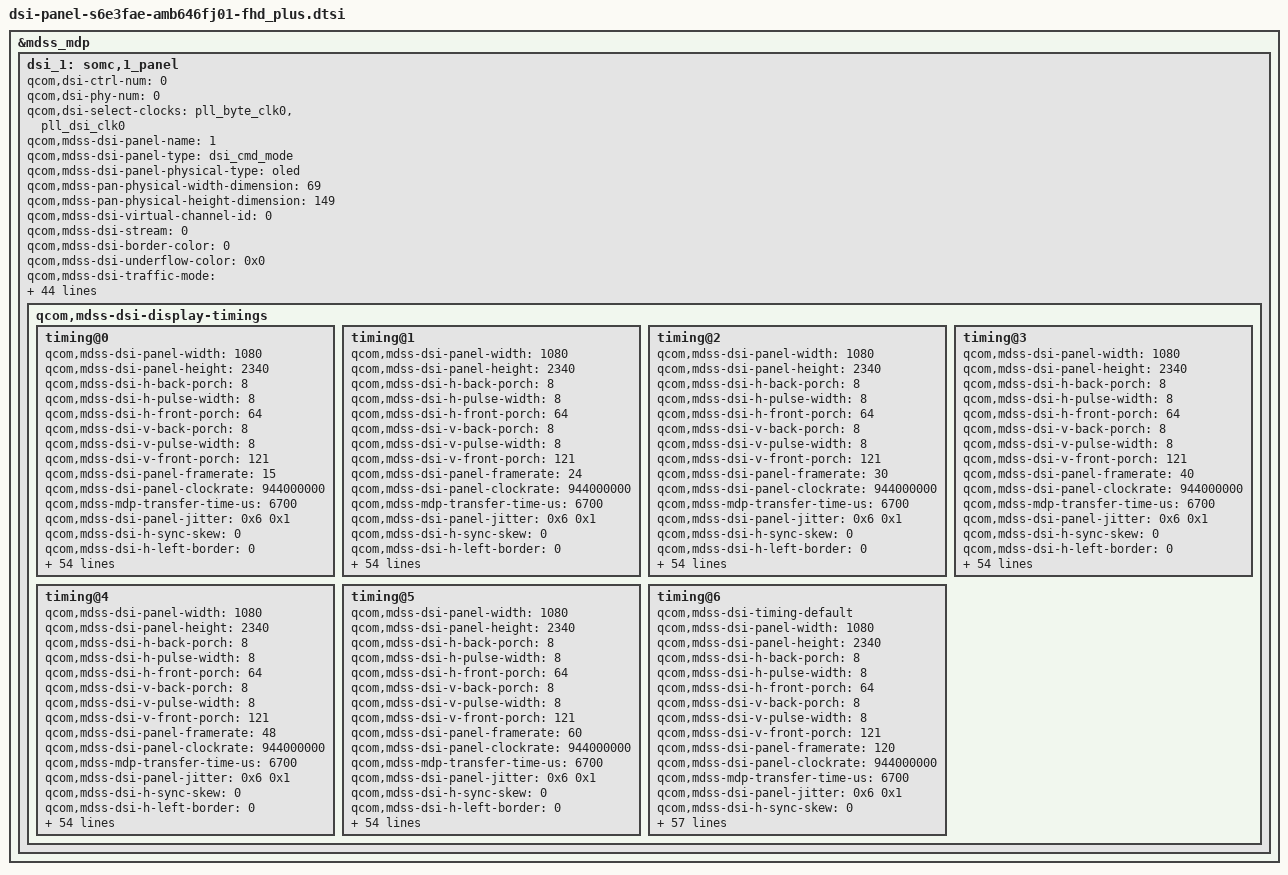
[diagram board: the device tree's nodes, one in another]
&mdss_mdp {
	/* Samsung FHD OLED ID1 */
	dsi_1: somc,1_panel {
		qcom,dsi-ctrl-num = <0>;
		qcom,dsi-phy-num = <0>;
		qcom,dsi-select-clocks = "pll_byte_clk0", "pll_dsi_clk0";

		qcom,mdss-dsi-panel-name = "1";
		qcom,mdss-dsi-panel-type = "dsi_cmd_mode";
		qcom,mdss-dsi-panel-physical-type = "oled";
		qcom,mdss-pan-physical-width-dimension = <69>;
		qcom,mdss-pan-physical-height-dimension = <149>;
		qcom,mdss-dsi-virtual-channel-id = <0>;
		qcom,mdss-dsi-stream = <0>;
		qcom,mdss-dsi-border-color = <0>;
		qcom,mdss-dsi-underflow-color = <0x0>;
		qcom,mdss-dsi-traffic-mode = "non_burst_sync_event";
		qcom,mdss-dsi-bllp-eof-power-mode;
		qcom,mdss-dsi-bllp-power-mode;
		qcom,mdss-dsi-dma-trigger = "trigger_sw";
		qcom,mdss-dsi-mdp-trigger = "none";
		qcom,mdss-dsi-te-using-te-pin;
		qcom,mdss-dsi-te-pin-select = <1>;
		qcom,mdss-dsi-te-dcs-command = <1>;
		qcom,mdss-dsi-te-check-enable;
		qcom,mdss-dsi-tx-eot-append;
		qcom,mdss-dsi-wr-mem-start = <0x2c>;
		qcom,mdss-dsi-wr-mem-continue = <0x3c>;
		qcom,mdss-dsi-bpp = <24>;
		qcom,mdss-dsi-lane-0-state;
		qcom,mdss-dsi-lane-1-state;
		qcom,mdss-dsi-lane-2-state;
		qcom,mdss-dsi-lane-3-state;
		qcom,mdss-dsi-lp11-init;

		somc,area_count_table_size = <45>;
		somc,area_count_table = <0 50 101 152 203
				254 306 357 408 459
				510 613 715 818 920
				1022 1125 1227 1330 1432
				1534 1637 1739 1842 1944
				2047 2162 2279 2396 2513
				2630 2747 2865 2982 3099
				3216 3333 3450 3567 3685
				3802 3919 4036 4094 4095>;

		somc,brightness-adjust-type = <2>;

		somc,pw-wait-before-on-lp11 = <10>;
		somc,mdss-dsi-touch-reset-sequence = <1 0>;
		somc,pw-wait-before-panel-reset = <1>;
		qcom,mdss-dsi-reset-sequence = <1 5>;

		somc,pw-wait-after-off-lp11 = <1>;
		somc,pw-off-rst-b-seq = <0 0>;
		somc,pw-wait-after-off-touch-vddh = <10>;
		somc,pw-wait-down_period = <100>;

		qcom,mdss-dsi-panel-peak-brightness = <15000000>;
		qcom,mdss-dsi-panel-blackness-level = <100>;
		qcom,mdss-dsi-panel-hdr-enabled;
		qcom,mdss-dsi-panel-hdr-color-primaries = <15335 15900 33905 15980 12475 35285 7205 2195>;

		qcom,esd-check-enabled;
		qcom,mdss-dsi-panel-status-command = [06 01 00 01 05 00 01 0A];
		qcom,mdss-dsi-panel-status-command-state = "dsi_lp_mode";
		qcom,mdss-dsi-panel-status-check-mode = "reg_read";
		qcom,mdss-dsi-panel-status-read-length = <1>;
		qcom,mdss-dsi-panel-status-value = <0x9f>;

		qcom,mdss-dsi-display-timings {
			/* FHD 15FPS */
			timing@0 {
				qcom,mdss-dsi-panel-width = <1080>;
				qcom,mdss-dsi-panel-height = <2340>;
				qcom,mdss-dsi-h-back-porch = <8>;
				qcom,mdss-dsi-h-pulse-width = <8>;
				qcom,mdss-dsi-h-front-porch = <64>;
				qcom,mdss-dsi-v-back-porch = <8>;
				qcom,mdss-dsi-v-pulse-width = <8>;
				qcom,mdss-dsi-v-front-porch = <121>;
				qcom,mdss-dsi-panel-framerate = <15>;
				qcom,mdss-dsi-panel-clockrate = <944000000>;
				qcom,mdss-mdp-transfer-time-us = <6700>;
				qcom,mdss-dsi-panel-jitter = <0x6 0x1>;
				qcom,mdss-dsi-h-sync-skew = <0>;
				qcom,mdss-dsi-h-left-border = <0>;
				qcom,mdss-dsi-h-right-border = <0>;
				qcom,mdss-dsi-v-top-border = <0>;
				qcom,mdss-dsi-v-bottom-border = <0>;
				qcom,mdss-dsi-h-sync-pulse = <1>;
				qcom,mdss-dsi-on-command-state = "dsi_lp_mode";
				qcom,mdss-dsi-post-on-command-state = "dsi_lp_mode";
				qcom,mdss-dsi-off-command-state = "dsi_hs_mode";

				qcom,compression-mode = "dsc";
				qcom,mdss-dsc-slice-height = <60>;
				qcom,mdss-dsc-slice-width = <540>;
				qcom,mdss-dsc-slice-per-pkt = <2>;
				qcom,mdss-dsc-bit-per-component = <8>;
				qcom,mdss-dsc-bit-per-pixel = <8>;
				qcom,mdss-dsc-encoders = <2>;
				qcom,mdss-dsc-block-prediction-enable;

				qcom,mdss-dsi-on-command = [
					05 01 00 00 78 00 01 11
					/* 245 */
					39 01 00 00 00 00 03 F0 5A 5A
					39 01 00 00 00 00 04 B0 00 01 F2
					39 01 00 00 00 00 02 F2 00
					39 01 00 00 00 00 02 F7 2F
					39 01 00 00 00 00 03 F0 A5 A5
					/* 245 */
					39 01 00 00 00 00 02 35 00
					39 01 00 00 00 00 05 2A 00 00 04 37
					39 01 00 00 00 00 05 2B 00 00 09 23
					39 01 00 00 00 00 03 F0 5A 5A
					39 01 00 00 00 00 04 B0 00 10 BD
					39 01 00 00 00 00 02 BD 00
					39 01 00 00 00 00 02 83 06
					39 01 00 00 00 00 04 B0 00 01 BD
					39 01 00 00 00 00 02 BD 81
					39 01 00 00 00 00 02 BD 01
					39 01 00 00 00 00 02 F7 2F
					39 01 00 00 00 00 03 F0 A5 A5
					39 01 00 00 00 00 03 F0 5A 5A
					39 01 00 00 00 00 03 FC 5A 5A
					39 01 00 00 00 00 04 B0 00 3C C5
					39 01 00 00 00 00 03 C5 43 A9
					39 01 00 00 00 00 04 B0 00 36 C5
					39 01 00 00 00 00 05 C5 11 10 50 05
					39 01 00 00 00 00 03 FC A5 A5
					39 01 00 00 00 00 03 F0 A5 A5
					39 01 00 00 00 00 02 55 00
					39 01 00 00 00 00 03 F0 5A 5A
					39 01 00 00 00 00 04 B0 00 08 68
					39 01 00 00 00 00 02 68 1E
					39 01 00 00 00 00 04 B0 00 03 68
					39 01 00 00 00 00 02 68 25
					39 01 00 00 00 00 03 F0 A5 A5
					39 01 00 00 00 00 03 F0 5A 5A
					39 01 00 00 00 00 02 E5 15
					39 01 00 00 00 00 04 B0 00 5F F4
					39 01 00 00 00 00 02 F4 F4
					39 01 00 00 00 00 04 B0 00 67 F4
					39 01 00 00 00 00 02 F4 AA
					39 01 00 00 00 00 04 B0 00 17 ED
					39 01 00 00 00 00 02 ED 1C
					39 01 00 00 00 00 03 ED 0B 4C
					39 01 00 00 00 00 04 B0 00 03 ED
					39 01 00 00 00 00 02 ED 0D
					39 01 00 00 00 00 03 F0 A5 A5
					39 01 00 00 00 00 02 53 28
					39 01 00 00 00 00 03 F0 5A 5A
					39 01 00 00 00 00 04 B0 00 17 69
					39 01 00 00 00 00 02 69 08
					39 01 00 00 00 00 02 F7 2F
					39 01 00 00 00 00 03 F0 A5 A5
					39 01 00 00 00 00 02 9D 01
					05 01 00 00 14 00 01 28
					39 01 00 00 00 00 03 F0 5A 5A
					39 01 00 00 00 00 02 B9 50
					39 01 00 00 00 00 02 F7 2F
					39 01 00 00 00 00 03 F0 A5 A5
					39 01 00 00 00 00 03 F0 5A 5A
					39 01 00 00 00 00 04 B0 00 10 BD
					39 01 00 00 00 00 02 BD 00
					39 01 00 00 00 00 02 83 00
					39 01 00 00 00 00 04 B0 00 01 BD
					39 01 00 00 00 00 02 BD 81
					39 01 00 00 00 00 02 BD 01
					39 01 00 00 00 00 02 F7 2F
					39 01 00 00 00 00 03 F0 A5 A5
					05 01 00 00 0A 00 01 28
					39 01 00 00 00 00 02 53 24
					39 01 00 00 00 00 03 51 02 80
					39 01 00 00 00 00 03 F0 5A 5A
					39 01 00 00 00 00 02 BD 01
					39 01 00 00 00 00 04 B0 00 02 BD
					39 01 00 00 00 00 02 BD 00
					39 01 00 00 00 00 04 B0 00 E8 BD
					39 01 00 00 00 00 02 BD 40
					39 01 00 00 00 00 04 B0 00 01 83
					39 01 00 00 00 00 02 83 01
					39 01 00 00 00 00 02 F7 2F
					39 01 00 00 00 00 03 F0 A5 A5
					05 01 00 00 00 00 01 29
					05 01 00 00 0A 00 01 28
					39 01 00 00 00 00 02 53 20
					39 01 00 00 00 00 03 51 00 04
					39 01 00 00 00 00 03 F0 5A 5A
					39 01 00 00 00 00 04 B0 00 10 BD
					39 01 00 00 00 00 02 BD 00
					39 01 00 00 00 00 02 83 06
					39 01 00 00 00 00 04 B0 00 01 BD
					39 01 00 00 00 00 02 BD 81
					39 01 00 00 00 00 02 BD 01
					39 01 00 00 00 00 02 F7 2F
					39 01 00 00 00 00 03 F0 A5 A5
					05 01 00 00 00 00 01 29
					];
				qcom,mdss-dsi-post-panel-on-command = [
					05 01 00 00 00 00 01 29];
				qcom,mdss-dsi-off-command = [
					05 01 00 00 14 00 01 28
					05 01 00 00 78 00 01 10];
				qcom,mdss-dsi-timing-switch-command = [
					39 01 00 00 00 00 03 F0 5A 5A
					39 01 00 00 00 00 04 B0 00 17 69
					39 01 00 00 00 00 02 69 08
					39 01 00 00 00 00 03 F0 A5 A5
					39 01 00 00 00 00 03 F0 5A 5A
					39 01 00 00 00 00 02 83 00
					39 01 00 00 00 00 02 F7 2F
					39 01 00 00 3C 00 03 F0 A5 A5
					39 01 00 00 00 00 03 F0 5A 5A
					39 01 00 00 00 00 02 B9 51
					39 01 00 00 00 00 04 B0 00 08 B9
					39 01 00 00 00 00 0D B9 00 09 44 00 00 20 00 09 44 00 00 20
					39 01 00 00 00 00 04 B0 00 02 B9
					39 01 00 00 00 00 02 B9 07
					39 01 00 00 00 00 02 B9 51
					39 01 00 00 00 00 02 F7 2F
					39 01 00 00 00 00 03 F0 A5 A5
					39 01 00 00 00 00 03 F0 5A 5A
					39 01 00 00 00 00 04 B0 00 93 BD
					39 01 00 00 00 00 02 BD 0E
					39 01 00 00 00 00 04 B0 00 83 BD
					39 01 00 00 00 00 02 BD 01
					39 01 00 00 00 00 04 B0 00 80 BD
					39 01 00 00 00 00 02 BD 16
					39 01 00 00 00 00 04 B0 00 9E BD
					39 01 00 00 00 00 11 BD 00 0E 00 0E 00 0E 00 0E 00 0E 00 0E 00 0E 00 0E
					39 01 00 00 00 00 04 B0 00 AE BD
					39 01 00 00 00 00 09 BD 00 00 00 00 00 00 00 00
					39 01 00 00 00 00 04 B0 00 1C BD
					39 01 00 00 00 00 02 BD EE
					39 01 00 00 00 00 04 B0 00 01 BD
					39 01 00 00 00 00 02 BD 01
					39 01 00 00 00 00 02 BD 83
					39 01 00 00 00 00 02 F7 2F
					39 01 00 00 00 00 03 F0 A5 A5
					05 01 00 00 00 00 01 29
					];
				qcom,mdss-dsi-timing-switch-command-state = "dsi_hs_mode";
				somc,mdss-dsi-flm2-on-command = [
					39 01 00 00 00 00 03 F0 5A 5A
					39 01 00 00 00 00 04 B0 00 03 68
					39 01 00 00 00 00 02 68 25
					39 01 00 00 00 00 03 F0 A5 A5
					];
				somc,mdss-dsi-flm2-off-command = [
					39 01 00 00 00 00 03 F0 5A 5A
					39 01 00 00 00 00 04 B0 00 03 68
					39 01 00 00 00 00 02 68 05
					39 01 00 00 00 00 03 F0 A5 A5
					];
				somc,mdss-dsi-flm2-on-command-state = "dsi_lp_mode";
				somc,mdss-dsi-flm2-off-command-state = "dsi_lp_mode";
				qcom,mdss-dsi-lp1-command = [
					05 01 00 00 14 00 01 28
					39 01 00 00 00 00 03 F0 5A 5A
					39 01 00 00 00 00 02 B9 50
					39 01 00 00 00 00 02 F7 2F
					39 01 00 00 00 00 03 F0 A5 A5
					39 01 00 00 00 00 03 F0 5A 5A
					39 01 00 00 00 00 04 B0 00 10 BD
					39 01 00 00 00 00 02 BD 00
					39 01 00 00 00 00 02 83 00
					39 01 00 00 00 00 04 B0 00 01 BD
					39 01 00 00 00 00 02 BD 81
					39 01 00 00 00 00 02 BD 01
					39 01 00 00 00 00 02 F7 2F
					39 01 00 00 00 00 03 F0 A5 A5
					05 01 00 00 0A 00 01 28
					39 01 00 00 00 00 02 53 24
					39 01 00 00 00 00 03 51 02 80
					39 01 00 00 00 00 03 F0 5A 5A
					39 01 00 00 00 00 02 BD 01
					39 01 00 00 00 00 04 B0 00 02 BD
					39 01 00 00 00 00 02 BD 00
					39 01 00 00 00 00 04 B0 00 E8 BD
					39 01 00 00 00 00 02 BD 40
					39 01 00 00 00 00 04 B0 00 01 83
					39 01 00 00 00 00 02 83 01
					39 01 00 00 00 00 02 F7 2F
					39 01 00 00 00 00 03 F0 A5 A5
					05 01 00 00 00 00 01 29
					];
				qcom,mdss-dsi-nolp-command = [
					05 01 00 00 0A 00 01 28
					39 01 00 00 00 00 02 53 20
					39 01 00 00 00 00 03 51 00 04
					05 01 00 00 00 00 01 29
					/*dimming control*/
					39 01 00 00 00 00 02 53 28
					];
				qcom,mdss-dsi-lp1-command-state = "dsi_lp_mode";
				qcom,mdss-dsi-nolp-command-state = "dsi_lp_mode";
				somc,mdss-dsi-hmd-on-command = [
					];
				somc,mdss-dsi-hmd-off-command = [
					];
				somc,mdss-dsi-hmd-on-command-state = "dsi_hs_mode";
				somc,mdss-dsi-hmd-off-command-state = "dsi_hs_mode";

				somc,mdss-dsi-aod-low-command = [
					39 01 00 00 00 00 03 51 02 80
					];
				somc,mdss-dsi-aod-high-command = [
					39 01 00 00 00 00 03 51 07 FF
					];
				somc,mdss-dsi-aod-low-command-state = "dsi_lp_mode";
				somc,mdss-dsi-aod-high-command-state = "dsi_lp_mode";
			};

			/* FHD 24FPS */
			timing@1 {
				qcom,mdss-dsi-panel-width = <1080>;
				qcom,mdss-dsi-panel-height = <2340>;
				qcom,mdss-dsi-h-back-porch = <8>;
				qcom,mdss-dsi-h-pulse-width = <8>;
				qcom,mdss-dsi-h-front-porch = <64>;
				qcom,mdss-dsi-v-back-porch = <8>;
				qcom,mdss-dsi-v-pulse-width = <8>;
				qcom,mdss-dsi-v-front-porch = <121>;
				qcom,mdss-dsi-panel-framerate = <24>;
				qcom,mdss-dsi-panel-clockrate = <944000000>;
				qcom,mdss-mdp-transfer-time-us = <6700>;
				qcom,mdss-dsi-panel-jitter = <0x6 0x1>;
				qcom,mdss-dsi-h-sync-skew = <0>;
				qcom,mdss-dsi-h-left-border = <0>;
				qcom,mdss-dsi-h-right-border = <0>;
				qcom,mdss-dsi-v-top-border = <0>;
				qcom,mdss-dsi-v-bottom-border = <0>;
				qcom,mdss-dsi-h-sync-pulse = <1>;
				qcom,mdss-dsi-on-command-state = "dsi_lp_mode";
				qcom,mdss-dsi-post-on-command-state = "dsi_lp_mode";
				qcom,mdss-dsi-off-command-state = "dsi_hs_mode";

				qcom,compression-mode = "dsc";
				qcom,mdss-dsc-slice-height = <60>;
				qcom,mdss-dsc-slice-width = <540>;
				qcom,mdss-dsc-slice-per-pkt = <2>;
				qcom,mdss-dsc-bit-per-component = <8>;
				qcom,mdss-dsc-bit-per-pixel = <8>;
				qcom,mdss-dsc-encoders = <2>;
				qcom,mdss-dsc-block-prediction-enable;

				qcom,mdss-dsi-on-command = [
					05 01 00 00 78 00 01 11
					/* 245 */
					39 01 00 00 00 00 03 F0 5A 5A
					39 01 00 00 00 00 04 B0 00 01 F2
					39 01 00 00 00 00 02 F2 00
					39 01 00 00 00 00 02 F7 2F
					39 01 00 00 00 00 03 F0 A5 A5
					/* 245 */
					39 01 00 00 00 00 02 35 00
					39 01 00 00 00 00 05 2A 00 00 04 37
					39 01 00 00 00 00 05 2B 00 00 09 23
					39 01 00 00 00 00 03 F0 5A 5A
					39 01 00 00 00 00 04 B0 00 10 BD
					39 01 00 00 00 00 02 BD 00
					39 01 00 00 00 00 02 83 05
					39 01 00 00 00 00 04 B0 00 01 BD
					39 01 00 00 00 00 02 BD 81
					39 01 00 00 00 00 02 BD 01
					39 01 00 00 00 00 02 F7 2F
					39 01 00 00 00 00 03 F0 A5 A5
					39 01 00 00 00 00 03 F0 5A 5A
					39 01 00 00 00 00 03 FC 5A 5A
					39 01 00 00 00 00 04 B0 00 3C C5
					39 01 00 00 00 00 03 C5 43 A9
					39 01 00 00 00 00 04 B0 00 36 C5
					39 01 00 00 00 00 05 C5 11 10 50 05
					39 01 00 00 00 00 03 FC A5 A5
					39 01 00 00 00 00 03 F0 A5 A5
					39 01 00 00 00 00 02 55 00
					39 01 00 00 00 00 03 F0 5A 5A
					39 01 00 00 00 00 04 B0 00 08 68
					39 01 00 00 00 00 02 68 1E
					39 01 00 00 00 00 04 B0 00 03 68
					39 01 00 00 00 00 02 68 25
					39 01 00 00 00 00 03 F0 A5 A5
					39 01 00 00 00 00 03 F0 5A 5A
					39 01 00 00 00 00 02 E5 15
					39 01 00 00 00 00 04 B0 00 5F F4
					39 01 00 00 00 00 02 F4 F4
					39 01 00 00 00 00 04 B0 00 67 F4
					39 01 00 00 00 00 02 F4 AA
					39 01 00 00 00 00 04 B0 00 17 ED
					39 01 00 00 00 00 02 ED 1C
					39 01 00 00 00 00 03 ED 0B 4C
					39 01 00 00 00 00 04 B0 00 03 ED
					39 01 00 00 00 00 02 ED 0D
					39 01 00 00 00 00 03 F0 A5 A5
					39 01 00 00 00 00 02 53 28
					39 01 00 00 00 00 03 F0 5A 5A
					39 01 00 00 00 00 04 B0 00 17 69
					39 01 00 00 00 00 02 69 08
					39 01 00 00 00 00 02 F7 2F
					39 01 00 00 00 00 03 F0 A5 A5
					39 01 00 00 00 00 02 9D 01
					05 01 00 00 14 00 01 28
					39 01 00 00 00 00 03 F0 5A 5A
					39 01 00 00 00 00 02 B9 50
					39 01 00 00 00 00 02 F7 2F
					39 01 00 00 00 00 03 F0 A5 A5
					39 01 00 00 00 00 03 F0 5A 5A
					39 01 00 00 00 00 04 B0 00 10 BD
					39 01 00 00 00 00 02 BD 00
					39 01 00 00 00 00 02 83 00
					39 01 00 00 00 00 04 B0 00 01 BD
					39 01 00 00 00 00 02 BD 81
					39 01 00 00 00 00 02 BD 01
					39 01 00 00 00 00 02 F7 2F
					39 01 00 00 00 00 03 F0 A5 A5
					05 01 00 00 0A 00 01 28
					39 01 00 00 00 00 02 53 24
					39 01 00 00 00 00 03 51 02 80
					39 01 00 00 00 00 03 F0 5A 5A
					39 01 00 00 00 00 02 BD 01
					39 01 00 00 00 00 04 B0 00 02 BD
					39 01 00 00 00 00 02 BD 00
					39 01 00 00 00 00 04 B0 00 E8 BD
					39 01 00 00 00 00 02 BD 40
					39 01 00 00 00 00 04 B0 00 01 83
					39 01 00 00 00 00 02 83 01
					39 01 00 00 00 00 02 F7 2F
					39 01 00 00 00 00 03 F0 A5 A5
					05 01 00 00 00 00 01 29
					05 01 00 00 0A 00 01 28
					39 01 00 00 00 00 02 53 20
					39 01 00 00 00 00 03 51 00 04
					39 01 00 00 00 00 03 F0 5A 5A
					39 01 00 00 00 00 04 B0 00 10 BD
					39 01 00 00 00 00 02 BD 00
					39 01 00 00 00 00 02 83 05
					39 01 00 00 00 00 04 B0 00 01 BD
					39 01 00 00 00 00 02 BD 81
					39 01 00 00 00 00 02 BD 01
					39 01 00 00 00 00 02 F7 2F
					39 01 00 00 00 00 03 F0 A5 A5
					05 01 00 00 00 00 01 29
					];
				qcom,mdss-dsi-post-panel-on-command = [
					05 01 00 00 00 00 01 29];
				qcom,mdss-dsi-off-command = [
					05 01 00 00 14 00 01 28
					05 01 00 00 78 00 01 10];
				qcom,mdss-dsi-timing-switch-command = [
					39 01 00 00 00 00 03 F0 5A 5A
					39 01 00 00 00 00 02 B9 50
					39 01 00 00 00 00 02 F7 2F
					39 01 00 00 00 00 03 F0 A5 A5
					39 01 00 00 00 00 03 F0 5A 5A
					39 01 00 00 00 00 04 B0 00 10 BD
					39 01 00 00 00 00 02 BD 00
					39 01 00 00 00 00 02 83 05
					39 01 00 00 00 00 04 B0 00 01 BD
					39 01 00 00 00 00 02 BD 81
					39 01 00 00 00 00 02 BD 01
					39 01 00 00 00 00 02 F7 2F
					39 01 00 00 00 00 03 F0 A5 A5
					05 01 00 00 07 00 01 29
					];
				qcom,mdss-dsi-timing-switch-command-state = "dsi_hs_mode";
				somc,mdss-dsi-flm2-on-command = [
					39 01 00 00 00 00 03 F0 5A 5A
					39 01 00 00 00 00 04 B0 00 03 68
					39 01 00 00 00 00 02 68 25
					39 01 00 00 00 00 03 F0 A5 A5
					];
				somc,mdss-dsi-flm2-off-command = [
					39 01 00 00 00 00 03 F0 5A 5A
					39 01 00 00 00 00 04 B0 00 03 68
					39 01 00 00 00 00 02 68 05
					39 01 00 00 00 00 03 F0 A5 A5
					];
				somc,mdss-dsi-flm2-on-command-state = "dsi_lp_mode";
				somc,mdss-dsi-flm2-off-command-state = "dsi_lp_mode";
				qcom,mdss-dsi-lp1-command = [
					05 01 00 00 14 00 01 28
					39 01 00 00 00 00 03 F0 5A 5A
					39 01 00 00 00 00 02 B9 50
					39 01 00 00 00 00 02 F7 2F
					39 01 00 00 00 00 03 F0 A5 A5
					39 01 00 00 00 00 03 F0 5A 5A
					39 01 00 00 00 00 04 B0 00 10 BD
					39 01 00 00 00 00 02 BD 00
					39 01 00 00 00 00 02 83 00
					39 01 00 00 00 00 04 B0 00 01 BD
					39 01 00 00 00 00 02 BD 81
					39 01 00 00 00 00 02 BD 01
					39 01 00 00 00 00 02 F7 2F
					39 01 00 00 00 00 03 F0 A5 A5
					05 01 00 00 0A 00 01 28
					39 01 00 00 00 00 02 53 24
					39 01 00 00 00 00 03 51 02 80
					39 01 00 00 00 00 03 F0 5A 5A
					39 01 00 00 00 00 02 BD 01
					39 01 00 00 00 00 04 B0 00 02 BD
					39 01 00 00 00 00 02 BD 00
					39 01 00 00 00 00 04 B0 00 E8 BD
					39 01 00 00 00 00 02 BD 40
					39 01 00 00 00 00 04 B0 00 01 83
					39 01 00 00 00 00 02 83 01
					39 01 00 00 00 00 02 F7 2F
					39 01 00 00 00 00 03 F0 A5 A5
					05 01 00 00 00 00 01 29
					];
				qcom,mdss-dsi-nolp-command = [
					05 01 00 00 0A 00 01 28
					39 01 00 00 00 00 02 53 20
					39 01 00 00 00 00 03 51 00 04
					05 01 00 00 00 00 01 29
					/*dimming control*/
					39 01 00 00 00 00 02 53 28
					];
				qcom,mdss-dsi-lp1-command-state = "dsi_lp_mode";
				qcom,mdss-dsi-nolp-command-state = "dsi_lp_mode";
				somc,mdss-dsi-hmd-on-command = [
					];
				somc,mdss-dsi-hmd-off-command = [
					];
				somc,mdss-dsi-hmd-on-command-state = "dsi_hs_mode";
				somc,mdss-dsi-hmd-off-command-state = "dsi_hs_mode";

				somc,mdss-dsi-aod-low-command = [
					39 01 00 00 00 00 03 51 02 80
					];
				somc,mdss-dsi-aod-high-command = [
					39 01 00 00 00 00 03 51 07 FF
					];
				somc,mdss-dsi-aod-low-command-state = "dsi_lp_mode";
				somc,mdss-dsi-aod-high-command-state = "dsi_lp_mode";
			};

			/* FHD 30FPS */
			timing@2 {
				qcom,mdss-dsi-panel-width = <1080>;
				qcom,mdss-dsi-panel-height = <2340>;
				qcom,mdss-dsi-h-back-porch = <8>;
				qcom,mdss-dsi-h-pulse-width = <8>;
				qcom,mdss-dsi-h-front-porch = <64>;
				qcom,mdss-dsi-v-back-porch = <8>;
				qcom,mdss-dsi-v-pulse-width = <8>;
				qcom,mdss-dsi-v-front-porch = <121>;
				qcom,mdss-dsi-panel-framerate = <30>;
				qcom,mdss-dsi-panel-clockrate = <944000000>;
				qcom,mdss-mdp-transfer-time-us = <6700>;
				qcom,mdss-dsi-panel-jitter = <0x6 0x1>;
				qcom,mdss-dsi-h-sync-skew = <0>;
				qcom,mdss-dsi-h-left-border = <0>;
				qcom,mdss-dsi-h-right-border = <0>;
				qcom,mdss-dsi-v-top-border = <0>;
				qcom,mdss-dsi-v-bottom-border = <0>;
				qcom,mdss-dsi-h-sync-pulse = <1>;
				qcom,mdss-dsi-on-command-state = "dsi_lp_mode";
				qcom,mdss-dsi-post-on-command-state = "dsi_lp_mode";
				qcom,mdss-dsi-off-command-state = "dsi_hs_mode";

				qcom,compression-mode = "dsc";
				qcom,mdss-dsc-slice-height = <60>;
				qcom,mdss-dsc-slice-width = <540>;
				qcom,mdss-dsc-slice-per-pkt = <2>;
				qcom,mdss-dsc-bit-per-component = <8>;
				qcom,mdss-dsc-bit-per-pixel = <8>;
				qcom,mdss-dsc-encoders = <2>;
				qcom,mdss-dsc-block-prediction-enable;

				qcom,mdss-dsi-on-command = [
					05 01 00 00 78 00 01 11
					/* 245 */
					39 01 00 00 00 00 03 F0 5A 5A
					39 01 00 00 00 00 04 B0 00 01 F2
					39 01 00 00 00 00 02 F2 00
					39 01 00 00 00 00 02 F7 2F
					39 01 00 00 00 00 03 F0 A5 A5
					/* 245 */
					39 01 00 00 00 00 02 35 00
					39 01 00 00 00 00 05 2A 00 00 04 37
					39 01 00 00 00 00 05 2B 00 00 09 23
					39 01 00 00 00 00 03 F0 5A 5A
					39 01 00 00 00 00 04 B0 00 10 BD
					39 01 00 00 00 00 02 BD 00
					39 01 00 00 00 00 02 83 04
					39 01 00 00 00 00 04 B0 00 01 BD
					39 01 00 00 00 00 02 BD 81
					39 01 00 00 00 00 02 BD 01
					39 01 00 00 00 00 02 F7 2F
					39 01 00 00 00 00 03 F0 A5 A5
					39 01 00 00 00 00 03 F0 5A 5A
					39 01 00 00 00 00 03 FC 5A 5A
					39 01 00 00 00 00 04 B0 00 3C C5
					39 01 00 00 00 00 03 C5 43 A9
					39 01 00 00 00 00 04 B0 00 36 C5
					39 01 00 00 00 00 05 C5 11 10 50 05
					39 01 00 00 00 00 03 FC A5 A5
					39 01 00 00 00 00 03 F0 A5 A5
					39 01 00 00 00 00 02 55 00
					39 01 00 00 00 00 03 F0 5A 5A
					39 01 00 00 00 00 04 B0 00 08 68
					39 01 00 00 00 00 02 68 1E
					39 01 00 00 00 00 04 B0 00 03 68
					39 01 00 00 00 00 02 68 25
					39 01 00 00 00 00 03 F0 A5 A5
					39 01 00 00 00 00 03 F0 5A 5A
					39 01 00 00 00 00 02 E5 15
					39 01 00 00 00 00 04 B0 00 5F F4
					39 01 00 00 00 00 02 F4 F4
					39 01 00 00 00 00 04 B0 00 67 F4
					39 01 00 00 00 00 02 F4 AA
					39 01 00 00 00 00 04 B0 00 17 ED
					39 01 00 00 00 00 02 ED 1C
					39 01 00 00 00 00 03 ED 0B 4C
					39 01 00 00 00 00 04 B0 00 03 ED
					39 01 00 00 00 00 02 ED 0D
					39 01 00 00 00 00 03 F0 A5 A5
					39 01 00 00 00 00 02 53 28
					39 01 00 00 00 00 03 F0 5A 5A
					39 01 00 00 00 00 04 B0 00 17 69
					39 01 00 00 00 00 02 69 08
					39 01 00 00 00 00 02 F7 2F
					39 01 00 00 00 00 03 F0 A5 A5
					39 01 00 00 00 00 02 9D 01
					05 01 00 00 14 00 01 28
					39 01 00 00 00 00 03 F0 5A 5A
					39 01 00 00 00 00 02 B9 50
					39 01 00 00 00 00 02 F7 2F
					39 01 00 00 00 00 03 F0 A5 A5
					39 01 00 00 00 00 03 F0 5A 5A
					39 01 00 00 00 00 04 B0 00 10 BD
					39 01 00 00 00 00 02 BD 00
					39 01 00 00 00 00 02 83 00
					39 01 00 00 00 00 04 B0 00 01 BD
					39 01 00 00 00 00 02 BD 81
					39 01 00 00 00 00 02 BD 01
					39 01 00 00 00 00 02 F7 2F
					39 01 00 00 00 00 03 F0 A5 A5
					05 01 00 00 0A 00 01 28
					39 01 00 00 00 00 02 53 24
					39 01 00 00 00 00 03 51 02 80
					39 01 00 00 00 00 03 F0 5A 5A
					39 01 00 00 00 00 02 BD 01
					39 01 00 00 00 00 04 B0 00 02 BD
					39 01 00 00 00 00 02 BD 00
					39 01 00 00 00 00 04 B0 00 E8 BD
					39 01 00 00 00 00 02 BD 40
					39 01 00 00 00 00 04 B0 00 01 83
					39 01 00 00 00 00 02 83 01
					39 01 00 00 00 00 02 F7 2F
					39 01 00 00 00 00 03 F0 A5 A5
					05 01 00 00 00 00 01 29
					05 01 00 00 0A 00 01 28
					39 01 00 00 00 00 02 53 20
					39 01 00 00 00 00 03 51 00 04
					39 01 00 00 00 00 03 F0 5A 5A
					39 01 00 00 00 00 04 B0 00 10 BD
					39 01 00 00 00 00 02 BD 00
					39 01 00 00 00 00 02 83 04
					39 01 00 00 00 00 04 B0 00 01 BD
					39 01 00 00 00 00 02 BD 81
					39 01 00 00 00 00 02 BD 01
					39 01 00 00 00 00 02 F7 2F
					39 01 00 00 00 00 03 F0 A5 A5
					05 01 00 00 00 00 01 29
					];
				qcom,mdss-dsi-post-panel-on-command = [
					05 01 00 00 00 00 01 29];
				qcom,mdss-dsi-off-command = [
					05 01 00 00 14 00 01 28
					05 01 00 00 78 00 01 10];
				qcom,mdss-dsi-timing-switch-command = [
					39 01 00 00 00 00 03 F0 5A 5A
					39 01 00 00 00 00 04 B0 00 17 69
					39 01 00 00 00 00 02 69 08
					39 01 00 00 00 00 03 F0 A5 A5
					39 01 00 00 00 00 03 F0 5A 5A
					39 01 00 00 00 00 02 83 00
					39 01 00 00 00 00 02 F7 2F
					39 01 00 00 3C 00 03 F0 A5 A5
					39 01 00 00 00 00 03 F0 5A 5A
					39 01 00 00 00 00 04 B0 00 08 B9
					39 01 00 00 00 00 0D B9 00 09 44 00 00 20 00 09 44 00 00 20
					39 01 00 00 00 00 04 B0 00 02 B9
					39 01 00 00 00 00 02 B9 03
					39 01 00 00 00 00 02 B9 51
					39 01 00 00 00 00 02 F7 2F
					39 01 00 00 00 00 03 F0 A5 A5
					39 01 00 00 00 00 03 F0 5A 5A
					39 01 00 00 00 00 04 B0 00 93 BD
					39 01 00 00 00 00 02 BD 06
					39 01 00 00 00 00 04 B0 00 83 BD
					39 01 00 00 00 00 02 BD 01
					39 01 00 00 00 00 04 B0 00 80 BD
					39 01 00 00 00 00 02 BD 16
					39 01 00 00 00 00 04 B0 00 9E BD
					39 01 00 00 00 00 11 BD 00 06 00 06 00 06 00 06 00 06 00 06 00 06 00 06
					39 01 00 00 00 00 04 B0 00 AE BD
					39 01 00 00 00 00 09 BD 00 00 00 00 00 00 00 00
					39 01 00 00 00 00 04 B0 00 1C BD
					39 01 00 00 00 00 02 BD EE
					39 01 00 00 00 00 04 B0 00 01 BD
					39 01 00 00 00 00 02 BD 01
					39 01 00 00 00 00 02 BD 83
					39 01 00 00 00 00 02 F7 2F
					39 01 00 00 00 00 03 F0 A5 A5
					05 01 00 00 07 00 01 29
					];
				qcom,mdss-dsi-timing-switch-command-state = "dsi_hs_mode";
				somc,mdss-dsi-flm2-on-command = [
					39 01 00 00 00 00 03 F0 5A 5A
					39 01 00 00 00 00 04 B0 00 03 68
					39 01 00 00 00 00 02 68 25
					39 01 00 00 00 00 03 F0 A5 A5
					];
				somc,mdss-dsi-flm2-off-command = [
					39 01 00 00 00 00 03 F0 5A 5A
					39 01 00 00 00 00 04 B0 00 03 68
					39 01 00 00 00 00 02 68 05
					39 01 00 00 00 00 03 F0 A5 A5
					];
				somc,mdss-dsi-flm2-on-command-state = "dsi_lp_mode";
				somc,mdss-dsi-flm2-off-command-state = "dsi_lp_mode";
				qcom,mdss-dsi-lp1-command = [
					05 01 00 00 14 00 01 28
					39 01 00 00 00 00 03 F0 5A 5A
					39 01 00 00 00 00 02 B9 50
					39 01 00 00 00 00 02 F7 2F
					39 01 00 00 00 00 03 F0 A5 A5
					39 01 00 00 00 00 03 F0 5A 5A
					39 01 00 00 00 00 04 B0 00 10 BD
					39 01 00 00 00 00 02 BD 00
					39 01 00 00 00 00 02 83 00
					39 01 00 00 00 00 04 B0 00 01 BD
					39 01 00 00 00 00 02 BD 81
					39 01 00 00 00 00 02 BD 01
					39 01 00 00 00 00 02 F7 2F
					39 01 00 00 00 00 03 F0 A5 A5
					05 01 00 00 0A 00 01 28
					39 01 00 00 00 00 02 53 24
					39 01 00 00 00 00 03 51 02 80
					39 01 00 00 00 00 03 F0 5A 5A
					39 01 00 00 00 00 02 BD 01
					39 01 00 00 00 00 04 B0 00 02 BD
					39 01 00 00 00 00 02 BD 00
					39 01 00 00 00 00 04 B0 00 E8 BD
					39 01 00 00 00 00 02 BD 40
					39 01 00 00 00 00 04 B0 00 01 83
					39 01 00 00 00 00 02 83 01
					39 01 00 00 00 00 02 F7 2F
					39 01 00 00 00 00 03 F0 A5 A5
					05 01 00 00 00 00 01 29
					];
				qcom,mdss-dsi-nolp-command = [
					05 01 00 00 0A 00 01 28
					39 01 00 00 00 00 02 53 20
					39 01 00 00 00 00 03 51 00 04
					05 01 00 00 00 00 01 29
					/*dimming control*/
					39 01 00 00 00 00 02 53 28
					];
				qcom,mdss-dsi-lp1-command-state = "dsi_lp_mode";
				qcom,mdss-dsi-nolp-command-state = "dsi_lp_mode";
				somc,mdss-dsi-hmd-on-command = [
					];
				somc,mdss-dsi-hmd-off-command = [
					];
				somc,mdss-dsi-hmd-on-command-state = "dsi_hs_mode";
				somc,mdss-dsi-hmd-off-command-state = "dsi_hs_mode";

				somc,mdss-dsi-aod-low-command = [
					39 01 00 00 00 00 03 51 02 80
					];
				somc,mdss-dsi-aod-high-command = [
					39 01 00 00 00 00 03 51 07 FF
					];
				somc,mdss-dsi-aod-low-command-state = "dsi_lp_mode";
				somc,mdss-dsi-aod-high-command-state = "dsi_lp_mode";
			};

			/* FHD 40FPS */
			timing@3 {
				qcom,mdss-dsi-panel-width = <1080>;
				qcom,mdss-dsi-panel-height = <2340>;
				qcom,mdss-dsi-h-back-porch = <8>;
				qcom,mdss-dsi-h-pulse-width = <8>;
				qcom,mdss-dsi-h-front-porch = <64>;
				qcom,mdss-dsi-v-back-porch = <8>;
				qcom,mdss-dsi-v-pulse-width = <8>;
				qcom,mdss-dsi-v-front-porch = <121>;
				qcom,mdss-dsi-panel-framerate = <40>;
				qcom,mdss-dsi-panel-clockrate = <944000000>;
				qcom,mdss-mdp-transfer-time-us = <6700>;
				qcom,mdss-dsi-panel-jitter = <0x6 0x1>;
				qcom,mdss-dsi-h-sync-skew = <0>;
				qcom,mdss-dsi-h-left-border = <0>;
				qcom,mdss-dsi-h-right-border = <0>;
				qcom,mdss-dsi-v-top-border = <0>;
				qcom,mdss-dsi-v-bottom-border = <0>;
				qcom,mdss-dsi-h-sync-pulse = <1>;
				qcom,mdss-dsi-on-command-state = "dsi_lp_mode";
				qcom,mdss-dsi-post-on-command-state = "dsi_lp_mode";
				qcom,mdss-dsi-off-command-state = "dsi_hs_mode";

				qcom,compression-mode = "dsc";
				qcom,mdss-dsc-slice-height = <60>;
				qcom,mdss-dsc-slice-width = <540>;
				qcom,mdss-dsc-slice-per-pkt = <2>;
				qcom,mdss-dsc-bit-per-component = <8>;
				qcom,mdss-dsc-bit-per-pixel = <8>;
				qcom,mdss-dsc-encoders = <2>;
				qcom,mdss-dsc-block-prediction-enable;

				qcom,mdss-dsi-on-command = [
					05 01 00 00 78 00 01 11
					/* 245 */
					39 01 00 00 00 00 03 F0 5A 5A
					39 01 00 00 00 00 04 B0 00 01 F2
					39 01 00 00 00 00 02 F2 00
					39 01 00 00 00 00 02 F7 2F
					39 01 00 00 00 00 03 F0 A5 A5
					/* 245 */
					39 01 00 00 00 00 02 35 00
					39 01 00 00 00 00 05 2A 00 00 04 37
					39 01 00 00 00 00 05 2B 00 00 09 23
					39 01 00 00 00 00 03 F0 5A 5A
					39 01 00 00 00 00 04 B0 00 10 BD
					39 01 00 00 00 00 02 BD 00
					39 01 00 00 00 00 02 83 03
					39 01 00 00 00 00 04 B0 00 01 BD
					39 01 00 00 00 00 02 BD 81
					39 01 00 00 00 00 02 BD 01
					39 01 00 00 00 00 02 F7 2F
					39 01 00 00 00 00 03 F0 A5 A5
					39 01 00 00 00 00 03 F0 5A 5A
					39 01 00 00 00 00 03 FC 5A 5A
					39 01 00 00 00 00 04 B0 00 3C C5
					39 01 00 00 00 00 03 C5 43 A9
					39 01 00 00 00 00 04 B0 00 36 C5
					39 01 00 00 00 00 05 C5 11 10 50 05
					39 01 00 00 00 00 03 FC A5 A5
					39 01 00 00 00 00 03 F0 A5 A5
					39 01 00 00 00 00 02 55 00
					39 01 00 00 00 00 03 F0 5A 5A
					39 01 00 00 00 00 04 B0 00 08 68
					39 01 00 00 00 00 02 68 1E
					39 01 00 00 00 00 04 B0 00 03 68
					39 01 00 00 00 00 02 68 25
					39 01 00 00 00 00 03 F0 A5 A5
					39 01 00 00 00 00 03 F0 5A 5A
					39 01 00 00 00 00 02 E5 15
					39 01 00 00 00 00 04 B0 00 5F F4
					39 01 00 00 00 00 02 F4 F4
					39 01 00 00 00 00 04 B0 00 67 F4
					39 01 00 00 00 00 02 F4 AA
					39 01 00 00 00 00 04 B0 00 17 ED
					39 01 00 00 00 00 02 ED 1C
					39 01 00 00 00 00 03 ED 0B 4C
					39 01 00 00 00 00 04 B0 00 03 ED
					39 01 00 00 00 00 02 ED 0D
					39 01 00 00 00 00 03 F0 A5 A5
					39 01 00 00 00 00 02 53 28
					39 01 00 00 00 00 03 F0 5A 5A
					39 01 00 00 00 00 04 B0 00 17 69
					39 01 00 00 00 00 02 69 08
					39 01 00 00 00 00 02 F7 2F
					39 01 00 00 00 00 03 F0 A5 A5
					39 01 00 00 00 00 02 9D 01
					05 01 00 00 14 00 01 28
					39 01 00 00 00 00 03 F0 5A 5A
					39 01 00 00 00 00 02 B9 50
					39 01 00 00 00 00 02 F7 2F
					39 01 00 00 00 00 03 F0 A5 A5
					39 01 00 00 00 00 03 F0 5A 5A
					39 01 00 00 00 00 04 B0 00 10 BD
					39 01 00 00 00 00 02 BD 00
					39 01 00 00 00 00 02 83 00
					39 01 00 00 00 00 04 B0 00 01 BD
					39 01 00 00 00 00 02 BD 81
					39 01 00 00 00 00 02 BD 01
					39 01 00 00 00 00 02 F7 2F
					39 01 00 00 00 00 03 F0 A5 A5
					05 01 00 00 0A 00 01 28
					39 01 00 00 00 00 02 53 24
					39 01 00 00 00 00 03 51 02 80
					39 01 00 00 00 00 03 F0 5A 5A
					39 01 00 00 00 00 02 BD 01
					39 01 00 00 00 00 04 B0 00 02 BD
					39 01 00 00 00 00 02 BD 00
					39 01 00 00 00 00 04 B0 00 E8 BD
					39 01 00 00 00 00 02 BD 40
					39 01 00 00 00 00 04 B0 00 01 83
					39 01 00 00 00 00 02 83 01
					39 01 00 00 00 00 02 F7 2F
					39 01 00 00 00 00 03 F0 A5 A5
					05 01 00 00 00 00 01 29
					05 01 00 00 0A 00 01 28
					39 01 00 00 00 00 02 53 20
					39 01 00 00 00 00 03 51 00 04
					39 01 00 00 00 00 03 F0 5A 5A
					39 01 00 00 00 00 04 B0 00 10 BD
					39 01 00 00 00 00 02 BD 00
					39 01 00 00 00 00 02 83 03
					39 01 00 00 00 00 04 B0 00 01 BD
					39 01 00 00 00 00 02 BD 81
					39 01 00 00 00 00 02 BD 01
					39 01 00 00 00 00 02 F7 2F
					39 01 00 00 00 00 03 F0 A5 A5
					05 01 00 00 00 00 01 29
					];
				qcom,mdss-dsi-post-panel-on-command = [
					05 01 00 00 00 00 01 29];
				qcom,mdss-dsi-off-command = [
					05 01 00 00 14 00 01 28
					05 01 00 00 78 00 01 10];
				qcom,mdss-dsi-timing-switch-command = [
					39 01 00 00 00 00 03 F0 5A 5A
					39 01 00 00 00 00 02 B9 50
					39 01 00 00 00 00 02 F7 2F
					39 01 00 00 00 00 03 F0 A5 A5
					39 01 00 00 00 00 03 F0 5A 5A
					39 01 00 00 00 00 04 B0 00 10 BD
					39 01 00 00 00 00 02 BD 00
					39 01 00 00 00 00 02 83 03
					39 01 00 00 00 00 04 B0 00 01 BD
					39 01 00 00 00 00 02 BD 81
					39 01 00 00 00 00 02 BD 01
					39 01 00 00 00 00 02 F7 2F
					39 01 00 00 00 00 03 F0 A5 A5
					05 01 00 00 07 00 01 29
					];
				qcom,mdss-dsi-timing-switch-command-state = "dsi_hs_mode";
				somc,mdss-dsi-flm2-on-command = [
					39 01 00 00 00 00 03 F0 5A 5A
					39 01 00 00 00 00 04 B0 00 03 68
					39 01 00 00 00 00 02 68 25
					39 01 00 00 00 00 03 F0 A5 A5
					];
				somc,mdss-dsi-flm2-off-command = [
					39 01 00 00 00 00 03 F0 5A 5A
					39 01 00 00 00 00 04 B0 00 03 68
					39 01 00 00 00 00 02 68 05
					39 01 00 00 00 00 03 F0 A5 A5
					];
				somc,mdss-dsi-flm2-on-command-state = "dsi_lp_mode";
				somc,mdss-dsi-flm2-off-command-state = "dsi_lp_mode";
				qcom,mdss-dsi-lp1-command = [
					05 01 00 00 14 00 01 28
					39 01 00 00 00 00 03 F0 5A 5A
					39 01 00 00 00 00 02 B9 50
					39 01 00 00 00 00 02 F7 2F
					39 01 00 00 00 00 03 F0 A5 A5
					39 01 00 00 00 00 03 F0 5A 5A
					39 01 00 00 00 00 04 B0 00 10 BD
					39 01 00 00 00 00 02 BD 00
					39 01 00 00 00 00 02 83 00
					39 01 00 00 00 00 04 B0 00 01 BD
					39 01 00 00 00 00 02 BD 81
					39 01 00 00 00 00 02 BD 01
					39 01 00 00 00 00 02 F7 2F
					39 01 00 00 00 00 03 F0 A5 A5
					05 01 00 00 0A 00 01 28
					39 01 00 00 00 00 02 53 24
					39 01 00 00 00 00 03 51 02 80
					39 01 00 00 00 00 03 F0 5A 5A
					39 01 00 00 00 00 02 BD 01
					39 01 00 00 00 00 04 B0 00 02 BD
					39 01 00 00 00 00 02 BD 00
					39 01 00 00 00 00 04 B0 00 E8 BD
					39 01 00 00 00 00 02 BD 40
					39 01 00 00 00 00 04 B0 00 01 83
					39 01 00 00 00 00 02 83 01
					39 01 00 00 00 00 02 F7 2F
					39 01 00 00 00 00 03 F0 A5 A5
					05 01 00 00 00 00 01 29
					];
				qcom,mdss-dsi-nolp-command = [
					05 01 00 00 0A 00 01 28
					39 01 00 00 00 00 02 53 20
					39 01 00 00 00 00 03 51 00 04
					05 01 00 00 00 00 01 29
					/*dimming control*/
					39 01 00 00 00 00 02 53 28
					];
				qcom,mdss-dsi-lp1-command-state = "dsi_lp_mode";
				qcom,mdss-dsi-nolp-command-state = "dsi_lp_mode";
				somc,mdss-dsi-hmd-on-command = [
					];
				somc,mdss-dsi-hmd-off-command = [
					];
				somc,mdss-dsi-hmd-on-command-state = "dsi_hs_mode";
				somc,mdss-dsi-hmd-off-command-state = "dsi_hs_mode";

				somc,mdss-dsi-aod-low-command = [
					39 01 00 00 00 00 03 51 02 80
					];
				somc,mdss-dsi-aod-high-command = [
					39 01 00 00 00 00 03 51 07 FF
					];
				somc,mdss-dsi-aod-low-command-state = "dsi_lp_mode";
				somc,mdss-dsi-aod-high-command-state = "dsi_lp_mode";
			};

			/* FHD 48FPS */
			timing@4 {
				qcom,mdss-dsi-panel-width = <1080>;
				qcom,mdss-dsi-panel-height = <2340>;
				qcom,mdss-dsi-h-back-porch = <8>;
				qcom,mdss-dsi-h-pulse-width = <8>;
				qcom,mdss-dsi-h-front-porch = <64>;
				qcom,mdss-dsi-v-back-porch = <8>;
				qcom,mdss-dsi-v-pulse-width = <8>;
				qcom,mdss-dsi-v-front-porch = <121>;
				qcom,mdss-dsi-panel-framerate = <48>;
				qcom,mdss-dsi-panel-clockrate = <944000000>;
				qcom,mdss-mdp-transfer-time-us = <6700>;
				qcom,mdss-dsi-panel-jitter = <0x6 0x1>;
				qcom,mdss-dsi-h-sync-skew = <0>;
				qcom,mdss-dsi-h-left-border = <0>;
				qcom,mdss-dsi-h-right-border = <0>;
				qcom,mdss-dsi-v-top-border = <0>;
				qcom,mdss-dsi-v-bottom-border = <0>;
				qcom,mdss-dsi-h-sync-pulse = <1>;
				qcom,mdss-dsi-on-command-state = "dsi_lp_mode";
				qcom,mdss-dsi-post-on-command-state = "dsi_lp_mode";
				qcom,mdss-dsi-off-command-state = "dsi_hs_mode";

				qcom,compression-mode = "dsc";
				qcom,mdss-dsc-slice-height = <60>;
				qcom,mdss-dsc-slice-width = <540>;
				qcom,mdss-dsc-slice-per-pkt = <2>;
				qcom,mdss-dsc-bit-per-component = <8>;
				qcom,mdss-dsc-bit-per-pixel = <8>;
				qcom,mdss-dsc-encoders = <2>;
				qcom,mdss-dsc-block-prediction-enable;

				qcom,mdss-dsi-on-command = [
					05 01 00 00 78 00 01 11
					/* 245 */
					39 01 00 00 00 00 03 F0 5A 5A
					39 01 00 00 00 00 04 B0 00 01 F2
					39 01 00 00 00 00 02 F2 00
					39 01 00 00 00 00 02 F7 2F
					39 01 00 00 00 00 03 F0 A5 A5
					/* 245 */
					39 01 00 00 00 00 02 35 00
					39 01 00 00 00 00 05 2A 00 00 04 37
					39 01 00 00 00 00 05 2B 00 00 09 23
					39 01 00 00 00 00 03 F0 5A 5A
					39 01 00 00 00 00 04 B0 00 10 BD
					39 01 00 00 00 00 02 BD 00
					39 01 00 00 00 00 02 83 02
					39 01 00 00 00 00 04 B0 00 01 BD
					39 01 00 00 00 00 02 BD 81
					39 01 00 00 00 00 02 BD 01
					39 01 00 00 00 00 02 F7 2F
					39 01 00 00 00 00 03 F0 A5 A5
					39 01 00 00 00 00 03 F0 5A 5A
					39 01 00 00 00 00 03 FC 5A 5A
					39 01 00 00 00 00 04 B0 00 3C C5
					39 01 00 00 00 00 03 C5 43 A9
					39 01 00 00 00 00 04 B0 00 36 C5
					39 01 00 00 00 00 05 C5 11 10 50 05
					39 01 00 00 00 00 03 FC A5 A5
					39 01 00 00 00 00 03 F0 A5 A5
					39 01 00 00 00 00 02 55 00
					39 01 00 00 00 00 03 F0 5A 5A
					39 01 00 00 00 00 04 B0 00 08 68
					39 01 00 00 00 00 02 68 1E
					39 01 00 00 00 00 04 B0 00 03 68
					39 01 00 00 00 00 02 68 25
					39 01 00 00 00 00 03 F0 A5 A5
					39 01 00 00 00 00 03 F0 5A 5A
					39 01 00 00 00 00 02 E5 15
					39 01 00 00 00 00 04 B0 00 5F F4
					39 01 00 00 00 00 02 F4 F4
					39 01 00 00 00 00 04 B0 00 67 F4
					39 01 00 00 00 00 02 F4 AA
					39 01 00 00 00 00 04 B0 00 17 ED
					39 01 00 00 00 00 02 ED 1C
					39 01 00 00 00 00 03 ED 0B 4C
					39 01 00 00 00 00 04 B0 00 03 ED
					39 01 00 00 00 00 02 ED 0D
					39 01 00 00 00 00 03 F0 A5 A5
					39 01 00 00 00 00 02 53 28
					39 01 00 00 00 00 03 F0 5A 5A
					39 01 00 00 00 00 04 B0 00 17 69
					39 01 00 00 00 00 02 69 08
					39 01 00 00 00 00 02 F7 2F
					39 01 00 00 00 00 03 F0 A5 A5
					39 01 00 00 00 00 02 9D 01
					05 01 00 00 14 00 01 28
					39 01 00 00 00 00 03 F0 5A 5A
					39 01 00 00 00 00 02 B9 50
					39 01 00 00 00 00 02 F7 2F
					39 01 00 00 00 00 03 F0 A5 A5
					39 01 00 00 00 00 03 F0 5A 5A
					39 01 00 00 00 00 04 B0 00 10 BD
					39 01 00 00 00 00 02 BD 00
					39 01 00 00 00 00 02 83 00
					39 01 00 00 00 00 04 B0 00 01 BD
					39 01 00 00 00 00 02 BD 81
					39 01 00 00 00 00 02 BD 01
					39 01 00 00 00 00 02 F7 2F
					39 01 00 00 00 00 03 F0 A5 A5
					05 01 00 00 0A 00 01 28
					39 01 00 00 00 00 02 53 24
					39 01 00 00 00 00 03 51 02 80
					39 01 00 00 00 00 03 F0 5A 5A
					39 01 00 00 00 00 02 BD 01
					39 01 00 00 00 00 04 B0 00 02 BD
					39 01 00 00 00 00 02 BD 00
					39 01 00 00 00 00 04 B0 00 E8 BD
					39 01 00 00 00 00 02 BD 40
					39 01 00 00 00 00 04 B0 00 01 83
					39 01 00 00 00 00 02 83 01
					39 01 00 00 00 00 02 F7 2F
					39 01 00 00 00 00 03 F0 A5 A5
					05 01 00 00 00 00 01 29
					05 01 00 00 0A 00 01 28
					39 01 00 00 00 00 02 53 20
					39 01 00 00 00 00 03 51 00 04
					39 01 00 00 00 00 03 F0 5A 5A
					39 01 00 00 00 00 04 B0 00 10 BD
					39 01 00 00 00 00 02 BD 00
					39 01 00 00 00 00 02 83 02
					39 01 00 00 00 00 04 B0 00 01 BD
					39 01 00 00 00 00 02 BD 81
					39 01 00 00 00 00 02 BD 01
					39 01 00 00 00 00 02 F7 2F
					39 01 00 00 00 00 03 F0 A5 A5
					05 01 00 00 00 00 01 29
					];
				qcom,mdss-dsi-post-panel-on-command = [
					05 01 00 00 00 00 01 29];
				qcom,mdss-dsi-off-command = [
					05 01 00 00 14 00 01 28
					05 01 00 00 78 00 01 10];
				qcom,mdss-dsi-timing-switch-command = [
					39 01 00 00 00 00 03 F0 5A 5A
					39 01 00 00 00 00 02 B9 50
					39 01 00 00 00 00 02 F7 2F
					39 01 00 00 00 00 03 F0 A5 A5
					39 01 00 00 00 00 03 F0 5A 5A
					39 01 00 00 00 00 04 B0 00 10 BD
					39 01 00 00 00 00 02 BD 00
					39 01 00 00 00 00 02 83 02
					39 01 00 00 00 00 04 B0 00 01 BD
					39 01 00 00 00 00 02 BD 81
					39 01 00 00 00 00 02 BD 01
					39 01 00 00 00 00 02 F7 2F
					39 01 00 00 00 00 03 F0 A5 A5
					05 01 00 00 07 00 01 29
					];
				qcom,mdss-dsi-timing-switch-command-state = "dsi_hs_mode";
				somc,mdss-dsi-flm2-on-command = [
					39 01 00 00 00 00 03 F0 5A 5A
					39 01 00 00 00 00 04 B0 00 03 68
					39 01 00 00 00 00 02 68 25
					39 01 00 00 00 00 03 F0 A5 A5
					];
				somc,mdss-dsi-flm2-off-command = [
					39 01 00 00 00 00 03 F0 5A 5A
					39 01 00 00 00 00 04 B0 00 03 68
					39 01 00 00 00 00 02 68 05
					39 01 00 00 00 00 03 F0 A5 A5
					];
				somc,mdss-dsi-flm2-on-command-state = "dsi_lp_mode";
				somc,mdss-dsi-flm2-off-command-state = "dsi_lp_mode";
				qcom,mdss-dsi-lp1-command = [
					05 01 00 00 14 00 01 28
					39 01 00 00 00 00 03 F0 5A 5A
					39 01 00 00 00 00 02 B9 50
					39 01 00 00 00 00 02 F7 2F
					39 01 00 00 00 00 03 F0 A5 A5
					39 01 00 00 00 00 03 F0 5A 5A
					39 01 00 00 00 00 04 B0 00 10 BD
					39 01 00 00 00 00 02 BD 00
					39 01 00 00 00 00 02 83 00
					39 01 00 00 00 00 04 B0 00 01 BD
					39 01 00 00 00 00 02 BD 81
					39 01 00 00 00 00 02 BD 01
					39 01 00 00 00 00 02 F7 2F
					39 01 00 00 00 00 03 F0 A5 A5
					05 01 00 00 0A 00 01 28
					39 01 00 00 00 00 02 53 24
					39 01 00 00 00 00 03 51 02 80
					39 01 00 00 00 00 03 F0 5A 5A
					39 01 00 00 00 00 02 BD 01
					39 01 00 00 00 00 04 B0 00 02 BD
					39 01 00 00 00 00 02 BD 00
					39 01 00 00 00 00 04 B0 00 E8 BD
					39 01 00 00 00 00 02 BD 40
					39 01 00 00 00 00 04 B0 00 01 83
					39 01 00 00 00 00 02 83 01
					39 01 00 00 00 00 02 F7 2F
					39 01 00 00 00 00 03 F0 A5 A5
					05 01 00 00 00 00 01 29
					];
				qcom,mdss-dsi-nolp-command = [
					05 01 00 00 0A 00 01 28
					39 01 00 00 00 00 02 53 20
					39 01 00 00 00 00 03 51 00 04
					05 01 00 00 00 00 01 29
					/*dimming control*/
					39 01 00 00 00 00 02 53 28
					];
				qcom,mdss-dsi-lp1-command-state = "dsi_lp_mode";
				qcom,mdss-dsi-nolp-command-state = "dsi_lp_mode";
				somc,mdss-dsi-hmd-on-command = [
					];
				somc,mdss-dsi-hmd-off-command = [
					];
				somc,mdss-dsi-hmd-on-command-state = "dsi_hs_mode";
				somc,mdss-dsi-hmd-off-command-state = "dsi_hs_mode";

				somc,mdss-dsi-aod-low-command = [
					39 01 00 00 00 00 03 51 02 80
					];
				somc,mdss-dsi-aod-high-command = [
					39 01 00 00 00 00 03 51 07 FF
					];
				somc,mdss-dsi-aod-low-command-state = "dsi_lp_mode";
				somc,mdss-dsi-aod-high-command-state = "dsi_lp_mode";
			};

			/* FHD 60FPS */
			timing@5 {
				qcom,mdss-dsi-panel-width = <1080>;
				qcom,mdss-dsi-panel-height = <2340>;
				qcom,mdss-dsi-h-back-porch = <8>;
				qcom,mdss-dsi-h-pulse-width = <8>;
				qcom,mdss-dsi-h-front-porch = <64>;
				qcom,mdss-dsi-v-back-porch = <8>;
				qcom,mdss-dsi-v-pulse-width = <8>;
				qcom,mdss-dsi-v-front-porch = <121>;
				qcom,mdss-dsi-panel-framerate = <60>;
				qcom,mdss-dsi-panel-clockrate = <944000000>;
				qcom,mdss-mdp-transfer-time-us = <6700>;
				qcom,mdss-dsi-panel-jitter = <0x6 0x1>;
				qcom,mdss-dsi-h-sync-skew = <0>;
				qcom,mdss-dsi-h-left-border = <0>;
				qcom,mdss-dsi-h-right-border = <0>;
				qcom,mdss-dsi-v-top-border = <0>;
				qcom,mdss-dsi-v-bottom-border = <0>;
				qcom,mdss-dsi-h-sync-pulse = <1>;
				qcom,mdss-dsi-on-command-state = "dsi_lp_mode";
				qcom,mdss-dsi-post-on-command-state = "dsi_lp_mode";
				qcom,mdss-dsi-off-command-state = "dsi_hs_mode";

				qcom,compression-mode = "dsc";
				qcom,mdss-dsc-slice-height = <60>;
				qcom,mdss-dsc-slice-width = <540>;
				qcom,mdss-dsc-slice-per-pkt = <2>;
				qcom,mdss-dsc-bit-per-component = <8>;
				qcom,mdss-dsc-bit-per-pixel = <8>;
				qcom,mdss-dsc-encoders = <2>;
				qcom,mdss-dsc-block-prediction-enable;

				qcom,mdss-dsi-on-command = [
					05 01 00 00 78 00 01 11
					/* 245 */
					39 01 00 00 00 00 03 F0 5A 5A
					39 01 00 00 00 00 04 B0 00 01 F2
					39 01 00 00 00 00 02 F2 00
					39 01 00 00 00 00 02 F7 2F
					39 01 00 00 00 00 03 F0 A5 A5
					/* 245 */
					39 01 00 00 00 00 02 35 00
					39 01 00 00 00 00 05 2A 00 00 04 37
					39 01 00 00 00 00 05 2B 00 00 09 23
					39 01 00 00 00 00 03 F0 5A 5A
					39 01 00 00 00 00 04 B0 00 10 BD
					39 01 00 00 00 00 02 BD 00
					39 01 00 00 00 00 02 83 01
					39 01 00 00 00 00 04 B0 00 01 BD
					39 01 00 00 00 00 02 BD 81
					39 01 00 00 00 00 02 BD 01
					39 01 00 00 00 00 02 F7 2F
					39 01 00 00 00 00 03 F0 A5 A5
					39 01 00 00 00 00 03 F0 5A 5A
					39 01 00 00 00 00 03 FC 5A 5A
					39 01 00 00 00 00 04 B0 00 3C C5
					39 01 00 00 00 00 03 C5 43 A9
					39 01 00 00 00 00 04 B0 00 36 C5
					39 01 00 00 00 00 05 C5 11 10 50 05
					39 01 00 00 00 00 03 FC A5 A5
					39 01 00 00 00 00 03 F0 A5 A5
					39 01 00 00 00 00 02 55 00
					39 01 00 00 00 00 03 F0 5A 5A
					39 01 00 00 00 00 04 B0 00 08 68
					39 01 00 00 00 00 02 68 1E
					39 01 00 00 00 00 04 B0 00 03 68
					39 01 00 00 00 00 02 68 25
					39 01 00 00 00 00 03 F0 A5 A5
					39 01 00 00 00 00 03 F0 5A 5A
					39 01 00 00 00 00 02 E5 15
					39 01 00 00 00 00 04 B0 00 5F F4
					39 01 00 00 00 00 02 F4 F4
					39 01 00 00 00 00 04 B0 00 67 F4
					39 01 00 00 00 00 02 F4 AA
					39 01 00 00 00 00 04 B0 00 17 ED
					39 01 00 00 00 00 02 ED 1C
					39 01 00 00 00 00 03 ED 0B 4C
					39 01 00 00 00 00 04 B0 00 03 ED
					39 01 00 00 00 00 02 ED 0D
					39 01 00 00 00 00 03 F0 A5 A5
					39 01 00 00 00 00 02 53 28
					39 01 00 00 00 00 03 F0 5A 5A
					39 01 00 00 00 00 04 B0 00 17 69
					39 01 00 00 00 00 02 69 08
					39 01 00 00 00 00 02 F7 2F
					39 01 00 00 00 00 03 F0 A5 A5
					39 01 00 00 00 00 02 9D 01
					05 01 00 00 14 00 01 28
					39 01 00 00 00 00 03 F0 5A 5A
					39 01 00 00 00 00 02 B9 50
					39 01 00 00 00 00 02 F7 2F
					39 01 00 00 00 00 03 F0 A5 A5
					39 01 00 00 00 00 03 F0 5A 5A
					39 01 00 00 00 00 04 B0 00 10 BD
					39 01 00 00 00 00 02 BD 00
					39 01 00 00 00 00 02 83 01
					39 01 00 00 00 00 04 B0 00 01 BD
					39 01 00 00 00 00 02 BD 81
					39 01 00 00 00 00 02 BD 01
					39 01 00 00 00 00 02 F7 2F
					39 01 00 00 00 00 03 F0 A5 A5
					05 01 00 00 14 00 01 28
					39 01 00 00 00 00 02 53 24
					39 01 00 00 00 00 03 51 02 80
					39 01 00 00 00 00 03 F0 5A 5A
					39 01 00 00 00 00 02 BD 01
					39 01 00 00 00 00 04 B0 00 02 BD
					39 01 00 00 00 00 02 BD 00
					39 01 00 00 00 00 04 B0 00 E8 BD
					39 01 00 00 00 00 02 BD 40
					39 01 00 00 00 00 04 B0 00 01 83
					39 01 00 00 00 00 02 83 01
					39 01 00 00 00 00 02 F7 2F
					39 01 00 00 00 00 03 F0 A5 A5
					05 01 00 00 00 00 01 29
					05 01 00 00 0A 00 01 28
					39 01 00 00 00 00 02 53 20
					39 01 00 00 00 00 03 51 00 04
					05 01 00 00 00 00 01 29
					39 01 00 00 00 00 03 F0 5A 5A
					39 01 00 00 00 00 04 B0 00 10 BD
					39 01 00 00 00 00 02 BD 00
					39 01 00 00 00 00 02 83 01
					39 01 00 00 00 00 04 B0 00 01 BD
					39 01 00 00 00 00 02 BD 81
					39 01 00 00 00 00 02 BD 01
					39 01 00 00 00 00 02 F7 2F
					39 01 00 00 00 00 03 F0 A5 A5
					];
				qcom,mdss-dsi-post-panel-on-command = [
					05 01 00 00 00 00 01 29];
				qcom,mdss-dsi-off-command = [
					05 01 00 00 14 00 01 28
					05 01 00 00 78 00 01 10];
				qcom,mdss-dsi-timing-switch-command = [
					39 01 00 00 00 00 03 F0 5A 5A
					39 01 00 00 00 00 02 B9 50
					39 01 00 00 00 00 02 F7 2F
					39 01 00 00 00 00 03 F0 A5 A5
					39 01 00 00 00 00 03 F0 5A 5A
					39 01 00 00 00 00 04 B0 00 10 BD
					39 01 00 00 00 00 02 BD 00
					39 01 00 00 00 00 02 83 01
					39 01 00 00 00 00 04 B0 00 01 BD
					39 01 00 00 00 00 02 BD 81
					39 01 00 00 00 00 02 BD 01
					39 01 00 00 00 00 02 F7 2F
					39 01 00 00 00 00 03 F0 A5 A5
					05 01 00 00 07 00 01 29
					];
				qcom,mdss-dsi-timing-switch-command-state = "dsi_hs_mode";
				somc,mdss-dsi-flm2-on-command = [
					39 01 00 00 00 00 03 F0 5A 5A
					39 01 00 00 00 00 04 B0 00 03 68
					39 01 00 00 00 00 02 68 25
					39 01 00 00 00 00 03 F0 A5 A5
					];
				somc,mdss-dsi-flm2-off-command = [
					39 01 00 00 00 00 03 F0 5A 5A
					39 01 00 00 00 00 04 B0 00 03 68
					39 01 00 00 00 00 02 68 05
					39 01 00 00 00 00 03 F0 A5 A5
					];
				somc,mdss-dsi-flm2-on-command-state = "dsi_lp_mode";
				somc,mdss-dsi-flm2-off-command-state = "dsi_lp_mode";
				qcom,mdss-dsi-lp1-command = [
					05 01 00 00 14 00 01 28
					39 01 00 00 00 00 03 F0 5A 5A
					39 01 00 00 00 00 02 B9 50
					39 01 00 00 00 00 02 F7 2F
					39 01 00 00 00 00 03 F0 A5 A5
					39 01 00 00 00 00 03 F0 5A 5A
					39 01 00 00 00 00 04 B0 00 10 BD
					39 01 00 00 00 00 02 BD 00
					39 01 00 00 00 00 02 83 01
					39 01 00 00 00 00 04 B0 00 01 BD
					39 01 00 00 00 00 02 BD 81
					39 01 00 00 00 00 02 BD 01
					39 01 00 00 00 00 02 F7 2F
					39 01 00 00 00 00 03 F0 A5 A5
					05 01 00 00 14 00 01 28
					39 01 00 00 00 00 02 53 24
					39 01 00 00 00 00 03 51 02 80
					39 01 00 00 00 00 03 F0 5A 5A
					39 01 00 00 00 00 02 BD 01
					39 01 00 00 00 00 04 B0 00 02 BD
					39 01 00 00 00 00 02 BD 00
					39 01 00 00 00 00 04 B0 00 E8 BD
					39 01 00 00 00 00 02 BD 40
					39 01 00 00 00 00 04 B0 00 01 83
					39 01 00 00 00 00 02 83 01
					39 01 00 00 00 00 02 F7 2F
					39 01 00 00 00 00 03 F0 A5 A5
					05 01 00 00 00 00 01 29
					];
				qcom,mdss-dsi-nolp-command = [
					05 01 00 00 0A 00 01 28
					39 01 00 00 00 00 02 53 20
					39 01 00 00 00 00 03 51 00 04
					05 01 00 00 00 00 01 29
					/*dimming control*/
					39 01 00 00 00 00 02 53 28
					];
				qcom,mdss-dsi-lp1-command-state = "dsi_lp_mode";
				qcom,mdss-dsi-nolp-command-state = "dsi_lp_mode";
				somc,mdss-dsi-hmd-on-command = [
					];
				somc,mdss-dsi-hmd-off-command = [
					];
				somc,mdss-dsi-hmd-on-command-state = "dsi_hs_mode";
				somc,mdss-dsi-hmd-off-command-state = "dsi_hs_mode";

				somc,mdss-dsi-aod-low-command = [
					39 01 00 00 00 00 03 51 02 80
					];
				somc,mdss-dsi-aod-high-command = [
					39 01 00 00 00 00 03 51 07 FF
					];
				somc,mdss-dsi-aod-low-command-state = "dsi_lp_mode";
				somc,mdss-dsi-aod-high-command-state = "dsi_lp_mode";
			};

			/* FHD 120FPS */
			timing@6 {
				qcom,mdss-dsi-timing-default;
				qcom,mdss-dsi-panel-width = <1080>;
				qcom,mdss-dsi-panel-height = <2340>;
				qcom,mdss-dsi-h-back-porch = <8>;
				qcom,mdss-dsi-h-pulse-width = <8>;
				qcom,mdss-dsi-h-front-porch = <64>;
				qcom,mdss-dsi-v-back-porch = <8>;
				qcom,mdss-dsi-v-pulse-width = <8>;
				qcom,mdss-dsi-v-front-porch = <121>;
				qcom,mdss-dsi-panel-framerate = <120>;
				qcom,mdss-dsi-panel-clockrate = <944000000>;
				qcom,mdss-mdp-transfer-time-us = <6700>;
				qcom,mdss-dsi-panel-jitter = <0x6 0x1>;
				qcom,mdss-dsi-h-sync-skew = <0>;
				qcom,mdss-dsi-h-left-border = <0>;
				qcom,mdss-dsi-h-right-border = <0>;
				qcom,mdss-dsi-v-top-border = <0>;
				qcom,mdss-dsi-v-bottom-border = <0>;
				qcom,mdss-dsi-h-sync-pulse = <1>;
				qcom,mdss-dsi-on-command-state = "dsi_lp_mode";
				qcom,mdss-dsi-post-on-command-state = "dsi_lp_mode";
				qcom,mdss-dsi-off-command-state = "dsi_hs_mode";

				qcom,compression-mode = "dsc";
				qcom,mdss-dsc-slice-height = <60>;
				qcom,mdss-dsc-slice-width = <540>;
				qcom,mdss-dsc-slice-per-pkt = <2>;
				qcom,mdss-dsc-bit-per-component = <8>;
				qcom,mdss-dsc-bit-per-pixel = <8>;
				qcom,mdss-dsc-encoders = <2>;
				qcom,mdss-dsc-block-prediction-enable;

				qcom,mdss-dsi-on-command = [
					05 01 00 00 78 00 01 11
					/* 245 */
					39 01 00 00 00 00 03 F0 5A 5A
					39 01 00 00 00 00 04 B0 00 01 F2
					39 01 00 00 00 00 02 F2 00
					39 01 00 00 00 00 02 F7 2F
					39 01 00 00 00 00 03 F0 A5 A5
					/* 245 */
					39 01 00 00 00 00 02 35 00
					39 01 00 00 00 00 05 2A 00 00 04 37
					39 01 00 00 00 00 05 2B 00 00 09 23
					39 01 00 00 00 00 03 F0 5A 5A
					39 01 00 00 00 00 04 B0 00 10 BD
					39 01 00 00 00 00 02 BD 00
					39 01 00 00 00 00 02 83 00
					39 01 00 00 00 00 04 B0 00 01 BD
					39 01 00 00 00 00 02 BD 81
					39 01 00 00 00 00 02 BD 01
					39 01 00 00 00 00 02 F7 2F
					39 01 00 00 00 00 03 F0 A5 A5
					39 01 00 00 00 00 03 F0 5A 5A
					39 01 00 00 00 00 03 FC 5A 5A
					39 01 00 00 00 00 04 B0 00 3C C5
					39 01 00 00 00 00 03 C5 43 A9
					39 01 00 00 00 00 04 B0 00 36 C5
					39 01 00 00 00 00 05 C5 11 10 50 05
					39 01 00 00 00 00 03 FC A5 A5
					39 01 00 00 00 00 03 F0 A5 A5
					39 01 00 00 00 00 02 55 00
					39 01 00 00 00 00 03 F0 5A 5A
					39 01 00 00 00 00 04 B0 00 08 68
					39 01 00 00 00 00 02 68 1E
					39 01 00 00 00 00 04 B0 00 03 68
					39 01 00 00 00 00 02 68 25
					39 01 00 00 00 00 03 F0 A5 A5
					39 01 00 00 00 00 03 F0 5A 5A
					39 01 00 00 00 00 02 E5 15
					39 01 00 00 00 00 04 B0 00 5F F4
					39 01 00 00 00 00 02 F4 F4
					39 01 00 00 00 00 04 B0 00 67 F4
					39 01 00 00 00 00 02 F4 AA
					39 01 00 00 00 00 04 B0 00 17 ED
					39 01 00 00 00 00 02 ED 1C
					39 01 00 00 00 00 03 ED 0B 4C
					39 01 00 00 00 00 04 B0 00 03 ED
					39 01 00 00 00 00 02 ED 0D
					39 01 00 00 00 00 03 F0 A5 A5
					39 01 00 00 00 00 02 53 28
					39 01 00 00 00 00 03 F0 5A 5A
					39 01 00 00 00 00 04 B0 00 17 69
					39 01 00 00 00 00 02 69 08
					39 01 00 00 00 00 02 F7 2F
					39 01 00 00 00 00 03 F0 A5 A5
					39 01 00 00 00 00 02 9D 01
					05 01 00 00 14 00 01 28
					39 01 00 00 00 00 03 F0 5A 5A
					39 01 00 00 00 00 02 B9 50
					39 01 00 00 00 00 02 F7 2F
					39 01 00 00 00 00 03 F0 A5 A5
					39 01 00 00 00 00 03 F0 5A 5A
					39 01 00 00 00 00 04 B0 00 10 BD
					39 01 00 00 00 00 02 BD 00
					39 01 00 00 00 00 02 83 00
					39 01 00 00 00 00 04 B0 00 01 BD
					39 01 00 00 00 00 02 BD 81
					39 01 00 00 00 00 02 BD 01
					39 01 00 00 00 00 02 F7 2F
					39 01 00 00 00 00 03 F0 A5 A5
					05 01 00 00 0A 00 01 28
					39 01 00 00 00 00 02 53 24
					39 01 00 00 00 00 03 51 02 80
					39 01 00 00 00 00 03 F0 5A 5A
					39 01 00 00 00 00 02 BD 01
					39 01 00 00 00 00 04 B0 00 02 BD
					39 01 00 00 00 00 02 BD 00
					39 01 00 00 00 00 04 B0 00 E8 BD
					39 01 00 00 00 00 02 BD 40
					39 01 00 00 00 00 04 B0 00 01 83
					39 01 00 00 00 00 02 83 01
					39 01 00 00 00 00 02 F7 2F
					39 01 00 00 00 00 03 F0 A5 A5
					05 01 00 00 00 00 01 29
					05 01 00 00 0A 00 01 28
					39 01 00 00 00 00 02 53 20
					39 01 00 00 00 00 03 51 00 04
					39 01 00 00 00 00 03 F0 5A 5A
					39 01 00 00 00 00 04 B0 00 10 BD
					39 01 00 00 00 00 02 BD 00
					39 01 00 00 00 00 02 83 00
					39 01 00 00 00 00 04 B0 00 01 BD
					39 01 00 00 00 00 02 BD 81
					39 01 00 00 00 00 02 BD 01
					39 01 00 00 00 00 02 F7 2F
					39 01 00 00 00 00 03 F0 A5 A5
					05 01 00 00 00 00 01 29
					];
				qcom,mdss-dsi-post-panel-on-command = [
					05 01 00 00 00 00 01 29];
				qcom,mdss-dsi-off-command = [
					05 01 00 00 14 00 01 28
					05 01 00 00 78 00 01 10];
				qcom,mdss-dsi-timing-switch-command = [
					39 01 00 00 00 00 03 F0 5A 5A
					39 01 00 00 00 00 02 B9 50
					39 01 00 00 00 00 02 F7 2F
					39 01 00 00 00 00 03 F0 A5 A5
					39 01 00 00 00 00 03 F0 5A 5A
					39 01 00 00 00 00 04 B0 00 10 BD
					39 01 00 00 00 00 02 BD 00
					39 01 00 00 00 00 02 83 00
					39 01 00 00 00 00 04 B0 00 01 BD
					39 01 00 00 00 00 02 BD 81
					39 01 00 00 00 00 02 BD 01
					39 01 00 00 00 00 02 F7 2F
					39 01 00 00 00 00 03 F0 A5 A5
					05 01 00 00 00 00 01 29
					];
				qcom,mdss-dsi-timing-switch-command-state = "dsi_hs_mode";
				somc,mdss-dsi-flm2-on-command = [
					39 01 00 00 00 00 03 F0 5A 5A
					39 01 00 00 00 00 04 B0 00 03 68
					39 01 00 00 00 00 02 68 25
					39 01 00 00 00 00 03 F0 A5 A5
					];
				somc,mdss-dsi-flm2-off-command = [
					39 01 00 00 00 00 03 F0 5A 5A
					39 01 00 00 00 00 04 B0 00 03 68
					39 01 00 00 00 00 02 68 05
					39 01 00 00 00 00 03 F0 A5 A5
					];
				somc,mdss-dsi-flm2-on-command-state = "dsi_lp_mode";
				somc,mdss-dsi-flm2-off-command-state = "dsi_lp_mode";
				qcom,mdss-dsi-lp1-command = [
					05 01 00 00 14 00 01 28
					39 01 00 00 00 00 03 F0 5A 5A
					39 01 00 00 00 00 02 B9 50
					39 01 00 00 00 00 02 F7 2F
					39 01 00 00 00 00 03 F0 A5 A5
					39 01 00 00 00 00 03 F0 5A 5A
					39 01 00 00 00 00 04 B0 00 10 BD
					39 01 00 00 00 00 02 BD 00
					39 01 00 00 00 00 02 83 00
					39 01 00 00 00 00 04 B0 00 01 BD
					39 01 00 00 00 00 02 BD 81
					39 01 00 00 00 00 02 BD 01
					39 01 00 00 00 00 02 F7 2F
					39 01 00 00 00 00 03 F0 A5 A5
					05 01 00 00 0A 00 01 28
					39 01 00 00 00 00 02 53 24
					39 01 00 00 00 00 03 51 02 80
					39 01 00 00 00 00 03 F0 5A 5A
					39 01 00 00 00 00 02 BD 01
					39 01 00 00 00 00 04 B0 00 02 BD
					39 01 00 00 00 00 02 BD 00
					39 01 00 00 00 00 04 B0 00 E8 BD
					39 01 00 00 00 00 02 BD 40
					39 01 00 00 00 00 04 B0 00 01 83
					39 01 00 00 00 00 02 83 01
					39 01 00 00 00 00 02 F7 2F
					39 01 00 00 00 00 03 F0 A5 A5
					05 01 00 00 00 00 01 29
					];
				qcom,mdss-dsi-nolp-command = [
					05 01 00 00 0A 00 01 28
					39 01 00 00 00 00 02 53 20
					39 01 00 00 00 00 03 51 00 04
					05 01 00 00 00 00 01 29
					/*dimming control*/
					39 01 00 00 00 00 02 53 28
					];
				qcom,mdss-dsi-lp1-command-state = "dsi_lp_mode";
				qcom,mdss-dsi-nolp-command-state = "dsi_lp_mode";
				somc,mdss-dsi-hmd-on-command = [
					39 01 00 00 00 00 02 53 20
					39 01 00 00 00 00 03 F0 5A 5A
					39 01 00 00 00 00 04 B0 00 43 CA
					39 01 00 00 00 00 03 CA 00 00
					39 01 00 00 00 00 02 F7 2F
					39 01 00 00 00 00 03 F0 A5 A5
					39 01 00 00 00 00 03 F0 5A 5A
					39 01 00 00 00 00 02 83 08
					39 01 00 00 00 00 02 F7 2F
					39 01 00 00 00 00 03 F0 A5 A5
					];
				somc,mdss-dsi-hmd-off-command = [
					39 01 00 00 00 00 02 53 28
					39 01 00 00 00 00 03 F0 5A 5A
					39 01 00 00 00 00 02 83 00
					39 01 00 00 00 00 02 F7 2F
					39 01 00 00 00 00 03 F0 A5 A5
					];
				somc,mdss-dsi-hmd-on-command-state = "dsi_hs_mode";
				somc,mdss-dsi-hmd-off-command-state = "dsi_hs_mode";

				somc,mdss-dsi-aod-low-command = [
					39 01 00 00 00 00 03 51 02 80
					];
				somc,mdss-dsi-aod-high-command = [
					39 01 00 00 00 00 03 51 07 FF
					];
				somc,mdss-dsi-aod-low-command-state = "dsi_lp_mode";
				somc,mdss-dsi-aod-high-command-state = "dsi_lp_mode";
			};
		};
	};
};
